# cslr_srio_001 register map
Vendor: Texas Instruments
Peripheral module from a debugger description file.
Registers are 32-bit, read-write, reset 0x0 unless marked. A register's access mark holds for its fields unless they carry their own. Offsets are as the file gives them; lines under a group give offsets from that group; [hi:lo] are bit positions; {n}, {i} and the like mark numbered series; 'fields as' and 'values as' point back to an identical list; <NAME> marks a mode.

## SRIO — 1x/4x Sreial RapidIO
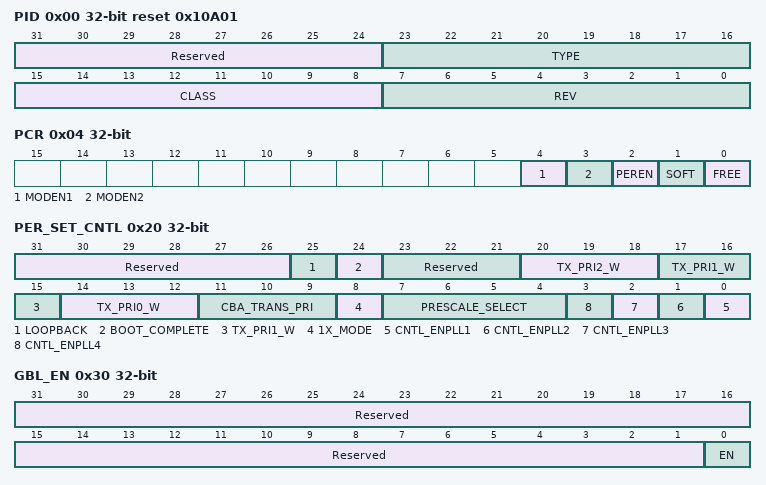
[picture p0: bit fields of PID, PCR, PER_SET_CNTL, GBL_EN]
0x00 PID access not given reset 0x10A01 (reset mask 0xFFFFFF) — Periperal Identification Register
  [31:24] Reserved — (access N)
  [23:16] TYPE ro — Type identifies the type of the peripheral RIO
  [15:8] CLASS ro — Class identifies the class switch fabric
  [7:0] REV ro — Revisions level of the specific instance of the peripheral
0x04 PCR — Peripheral Control Register
  [4] MODEN1 — Data Transmit Register(Read/Write)
  [3] MODEN2 — Data Transmit Register(Read/Write)
  [2] PEREN — Data Transmit Register(Read/Write)
  [1] SOFT — Data Transmit Register(Read/Write)
  [0] FREE — Data Transmit Register(Read/Write)
0x20 PER_SET_CNTL access not given (reset mask 0x31FFFFF)
  [31:26] Reserved — (access N)
  [25] LOOPBACK rw — Data Transmit Register(Read/Write)
  [24] BOOT_COMPLETE rw — Data Transmit Register(Read/Write)
  [23:21] Reserved — (access N)
  [20:18] TX_PRI2_W rw — Data Transmit Register(Read/Write)
  [17:15] TX_PRI1_W rw — Data Transmit Register(Read/Write)
  [14:12] TX_PRI0_W rw — Data Transmit Register(Read/Write)
  [11:9] CBA_TRANS_PRI rw — Data Transmit Register(Read/Write)
  [8] 1X_MODE rw — Data Transmit Register(Read/Write)
  [7:4] PRESCALE_SELECT rw — Data Transmit Register(Read/Write)
  [n-1] CNTL_ENPLL{n} rw (n=1..4) — Data Transmit Register(Read/Write)
0x30 GBL_EN access not given (reset mask 0x1) — Peripheral Global Enable
  [31:1] Reserved — (access N)
  [0] EN rw — Controls reset to all clock domains within the peripheral
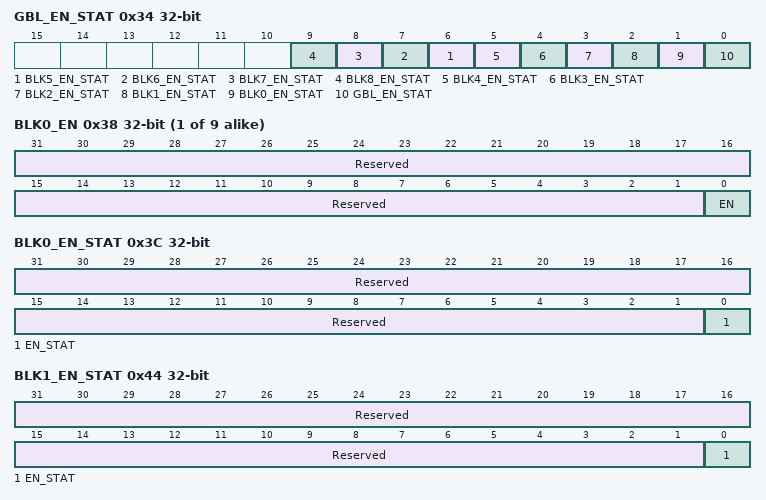
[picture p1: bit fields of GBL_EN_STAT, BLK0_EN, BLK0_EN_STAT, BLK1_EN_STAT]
0x34 GBL_EN_STAT ro
  [n+1] BLK{n}_EN_STAT (n=5..8) — Sample rate generator clock divider. This value is used as the divide-down number to generate the required sample rate generator clock frequency. Default value is 1.
  [5] BLK4_EN_STAT — Frame Width. Determines the width of the frame sync pulse, FSG, during its active period. Range: up to 28 ; 1 to 256 CLKG periods.
  [4] BLK3_EN_STAT — Frame Period. This determines when the next frame sync signal should become active. Range: up to 212 ; 1 to 4096 CLKG periods.
  [3] BLK2_EN_STAT — Sample Rate Generator Transmit frame synchronization mode. Used when FSXM=1 in PCR.
  [2] BLK1_EN_STAT — McBSP Sample Rate Generator Clock Mode
  [1] BLK0_EN_STAT — CLKS Polarity Clock Edge Select. Only used when the external clock CLKS drives the sample rate generator clock (CLKSM=0).
  [0] GBL_EN_STAT — Peripheral Global Enable Status
{0x38+8i} BLK{i}_EN access not given (reset mask 0x1) (i=0..8)
  [31:1] Reserved — (access N)
  [0] EN rw
0x3C BLK0_EN_STAT access not given (reset mask 0x1)
  [31:1] Reserved — (access N)
  [0] EN_STAT ro
    0=CHDISABLE
0x44 BLK1_EN_STAT access not given (reset mask 0x1)
  [31:1] Reserved — (access N)
  [0] EN_STAT ro
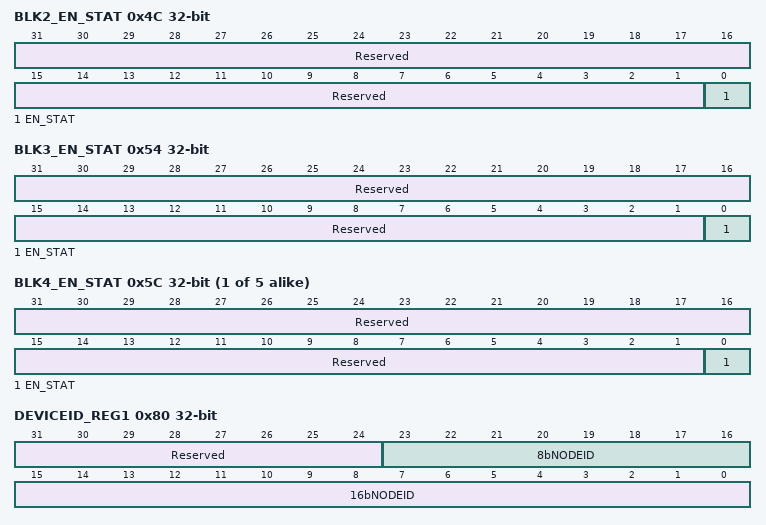
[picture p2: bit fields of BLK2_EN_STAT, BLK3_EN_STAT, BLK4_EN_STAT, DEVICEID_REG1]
0x4C BLK2_EN_STAT access not given (reset mask 0x1)
  [31:1] Reserved — (access N)
  [0] EN_STAT ro
0x54 BLK3_EN_STAT access not given (reset mask 0x1)
  [31:1] Reserved — (access N)
  [0] EN_STAT ro
    0=CHDISABLE
{0x3C+8i} BLK{i}_EN_STAT access not given (reset mask 0x1) (i=4..8)
  [31:1] Reserved — (access N)
  [0] EN_STAT ro
0x80 DEVICEID_REG1 access not given (reset mask 0xFFFFFF)
  [31:24] Reserved — (access N)
  [23:16] 8bNODEID rw
  [15:0] 16bNODEID rw
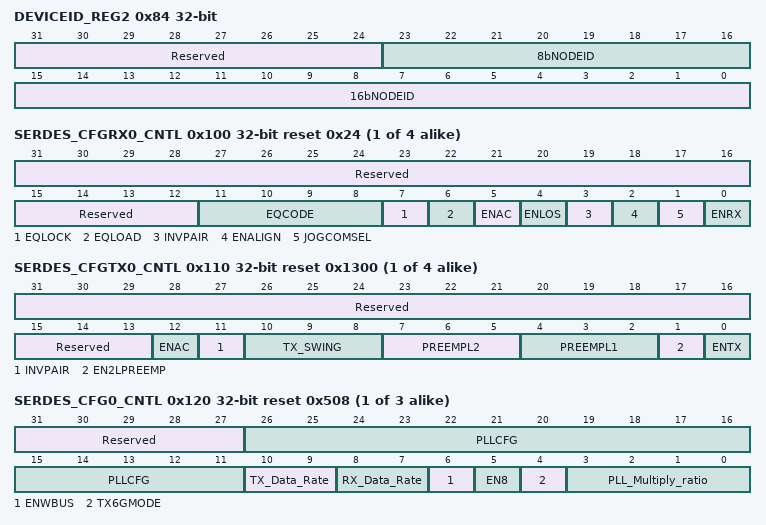
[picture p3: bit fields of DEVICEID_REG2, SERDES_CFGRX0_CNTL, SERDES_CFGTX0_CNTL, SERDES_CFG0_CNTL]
0x84 DEVICEID_REG2 access not given (reset mask 0xFFFFFF)
  fields as DEVICEID_REG1
{0x100+4i} SERDES_CFGRX{i}_CNTL access not given reset 0x24 (reset mask 0xFFF) (i=0..3) — SerDes CFGRX{i} Bus Register
  [31:12] Reserved — (access N)
  [11:8] EQCODE rw
  [7] EQLOCK rw
  [6] EQLOAD rw
  [5] ENAC rw
  [4] ENLOS rw
  [3] INVPAIR rw
  [2] ENALIGN rw
  [1] JOGCOMSEL rw
  [0] ENRX rw
{0x110+4i} SERDES_CFGTX{i}_CNTL access not given reset 0x1300 (reset mask 0x1FFF) (i=0..3) — SerDes TX Channel {i} CFG Regr
  [31:13] Reserved — (access N)
  [12] ENAC rw
  [11] INVPAIR rw
  [10:8] TX_SWING rw
  [7:5] PREEMPL2 rw
  [4:2] PREEMPL1 rw
  [1] EN2LPREEMP rw
  [0] ENTX rw
{0x120+4i} SERDES_CFG{i}_CNTL access not given reset 0x508 (reset mask 0x7FFFFFF) (i=0..2) — SerDes Macro {i}CFG Control Reg
  [31:27] Reserved — (access N)
  [26:11] PLLCFG rw
  [10:9] TX_Data_Rate rw
  [8:7] RX_Data_Rate rw
  [6] ENWBUS rw
  [5] EN8 rw
  [4] TX6GMODE rw
  [3:0] PLL_Multiply_ratio rw
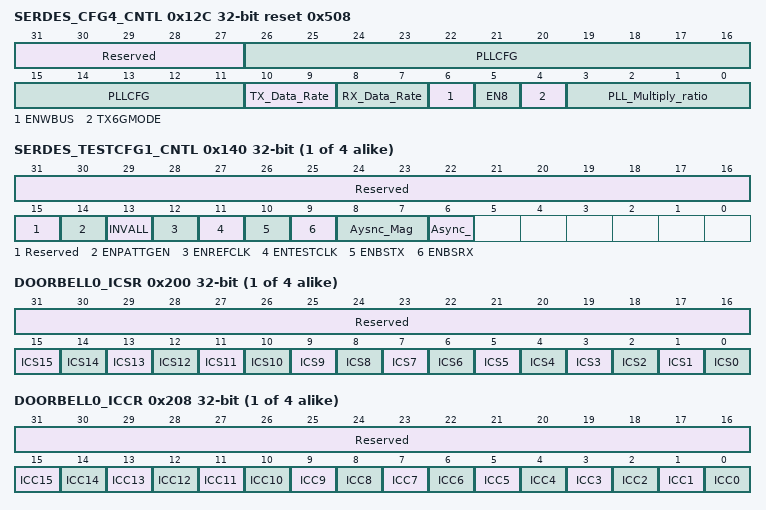
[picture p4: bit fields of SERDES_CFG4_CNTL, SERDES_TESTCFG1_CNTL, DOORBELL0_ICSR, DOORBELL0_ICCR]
0x12C SERDES_CFG4_CNTL access not given reset 0x508 (reset mask 0x7FFFFFF) — SerDes Macro 3CFG Control Reg
  fields as SERDES_CFG0_CNTL
{0x13C+4i} SERDES_TESTCFG{i}_CNTL access not given (reset mask 0x7FFF) (i=1..4) — SerDes TESTCFG BUS Register
  [31:15] Reserved — (access N)
  [14] ENPATTGEN rw
  [13] INVALL rw
  [12] ENREFCLK rw
  [11] ENTESTCLK rw
  [10] ENBSTX rw
  [9] ENBSRX rw
  [8:7] Aysnc_Mag rw
  [6] Async_
Polarity rw
  [5] Async_Ramp rw
  [4:2] TESTPATT rw
  [1] PADL rw
  [0] LOOPBACK rw
{0x200+0x10*i} DOORBELL{i}_ICSR access not given (reset mask 0xFFFF) (i=0..3) — Interrupt Condition Status Register (ICSR)
  [31:16] Reserved — (access N)
  [n] ICS{n} rw (n=0..15)
{0x208+0x10*i} DOORBELL{i}_ICCR access not given (reset mask 0xFFFF) (i=0..3) — Interrupt Condition Clear Register (ICCR)
  [31:16] Reserved — (access N)
  [n] ICC{n} rw (n=0..15)
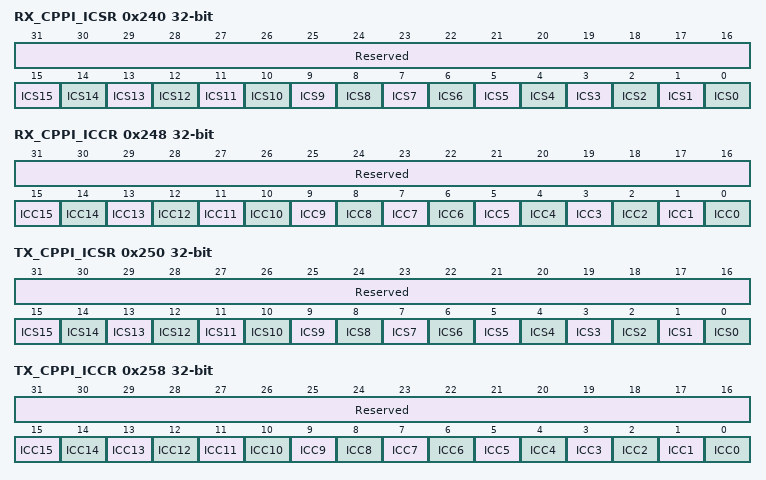
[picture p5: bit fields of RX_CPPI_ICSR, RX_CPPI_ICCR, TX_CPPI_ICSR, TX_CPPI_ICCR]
0x240 RX_CPPI_ICSR access not given (reset mask 0xFFFF) — RIO_RX_CPPI Interrupt Condition Status Register (ICSR)
  [31:16] Reserved — (access N)
  [n] ICS{n} rw (n=0..15)
0x248 RX_CPPI_ICCR access not given (reset mask 0xFFFF) — RIO_RX_CPPI Interrupt Condition Clear Register (ICCR)
  [31:16] Reserved — (access N)
  [n] ICC{n} rw (n=0..15)
0x250 TX_CPPI_ICSR access not given (reset mask 0xFFFF) — RIO_TX_CPPI Interrupt Condition Status Register (ICSR)
  [31:16] Reserved — (access N)
  [n] ICS{n} rw (n=0..15)
0x258 TX_CPPI_ICCR access not given (reset mask 0xFFFF) — RIO_TX_CPPI Interrupt Condition Clear Register (ICCR)
  [31:16] Reserved — (access N)
  [n] ICC{n} rw (n=0..15)
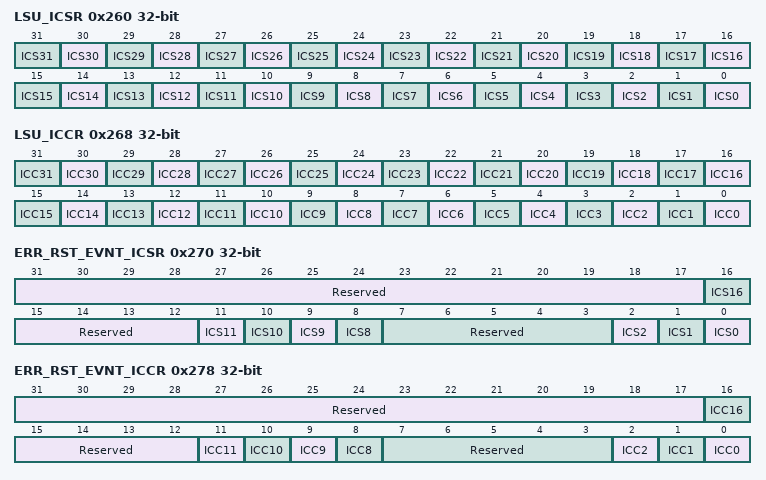
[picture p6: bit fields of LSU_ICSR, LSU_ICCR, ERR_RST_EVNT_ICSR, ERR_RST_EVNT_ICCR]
0x260 LSU_ICSR — LSU Load/Store Module Interrupts Condition Status Register (ICSR)
  [n] ICS{n} (n=0..31)
0x268 LSU_ICCR — LSU Load/Store Module Interrupts Condition Clear Register (ICCR)
  [n] ICC{n} (n=0..31)
0x270 ERR_RST_EVNT_ICSR access not given (reset mask 0x10F07) — ERR_RST_EVNT Error, Reset, and Special Event Interrupt Condition Status Register (ICSR)
  [31:17] Reserved — (access N)
  [16] ICS16 rw
  [15:12] Reserved — (access N)
  [n] ICS{n} rw (n=8..11)
  [7:3] Reserved — (access N)
  [2] ICS2 rw
  [1] ICS1 rw
  [0] ICS0 rw
0x278 ERR_RST_EVNT_ICCR access not given (reset mask 0x10F07) — ERR_RST_EVNT Error, Reset, and Special Event Interrupt Condition Clear Register (ICCR)
  [31:17] Reserved — (access N)
  [16] ICC16 rw
  [15:12] Reserved — (access N)
  [n] ICC{n} rw (n=8..11)
  [7:3] Reserved — (access N)
  [2] ICC2 rw
  [1] ICC1 rw
  [0] ICC0 rw
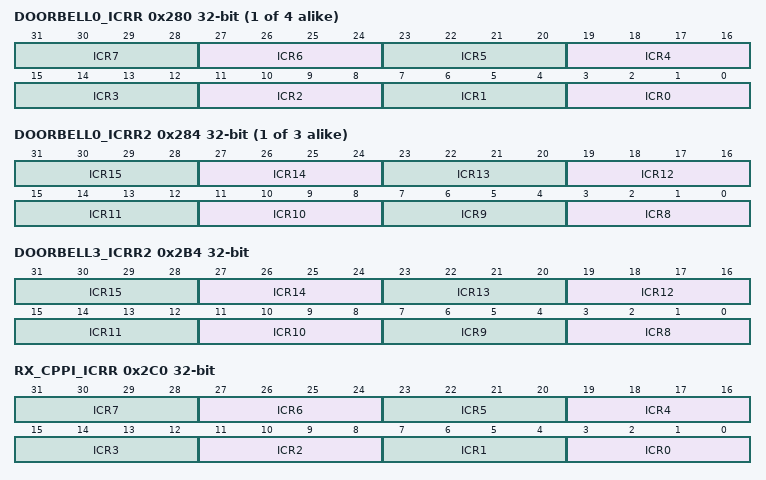
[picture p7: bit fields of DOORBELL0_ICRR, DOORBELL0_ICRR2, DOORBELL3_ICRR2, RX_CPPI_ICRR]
{0x280+0x10*i} DOORBELL{i}_ICRR (i=0..3) — DOORBELL{i}_ICRR CPU Servicing Interrupt Condition Routing Register (ICRR)
  [4n+3:4n] ICR{n} (n=0..7)
{0x284+0x10*i} DOORBELL{i}_ICRR2 (i=0..2) — DOORBELL{i}_ICRR2 CPU Servicing Interrupt Condition Routing Register (ICRR)
  [4n-29:4n-32] ICR{n} (n=8..15)
0x2B4 DOORBELL3_ICRR2 — DOORBELL3_ICRR2 CPU Servicing Interrupt Condition Routing Register (ICCR)
  [4n-29:4n-32] ICR{n} (n=8..15)
0x2C0 RX_CPPI_ICRR — RX CPPI CPU Servicing Interrupt Condition Routing Register (ICRR)
  [4n+3:4n] ICR{n} (n=0..7)
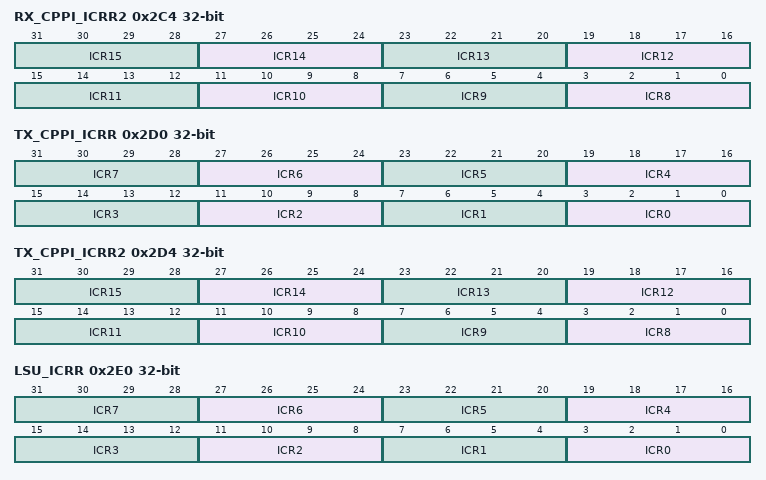
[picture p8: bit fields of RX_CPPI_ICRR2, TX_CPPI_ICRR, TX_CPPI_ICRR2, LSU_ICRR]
0x2C4 RX_CPPI_ICRR2 — RX CPPI CPU Servicing Interrupt Condition Routing Register (ICCR)
  [4n-29:4n-32] ICR{n} (n=8..15)
0x2D0 TX_CPPI_ICRR — TX CPPI CPU Servicing Interrupt Condition Routing Register (ICRR)
  [4n+3:4n] ICR{n} (n=0..7)
0x2D4 TX_CPPI_ICRR2 — TX CPPI CPU Servicing Interrupt Condition Routing Register (ICRR)
  [4n-29:4n-32] ICR{n} (n=8..15)
0x2E0 LSU_ICRR — Load/Store Module Interrupt Condition Routing Register (ICRR)
  [4n+3:4n] ICR{n} (n=0..7)
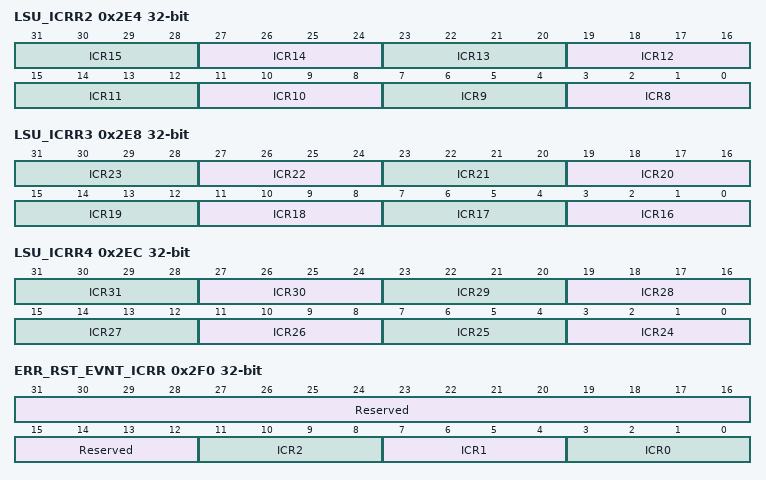
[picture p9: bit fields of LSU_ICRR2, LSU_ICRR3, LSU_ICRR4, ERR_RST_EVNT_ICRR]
0x2E4 LSU_ICRR2 — Load/Store Module Interrupt Condition Routing Register (ICRR)
  [4n-29:4n-32] ICR{n} (n=8..15)
0x2E8 LSU_ICRR3 — Load/Store Module Interrupt Condition Routing Register (ICRR)
  [4n-61:4n-64] ICR{n} (n=16..23)
0x2EC LSU_ICRR4 — Load/Store Module Interrupt Condition Routing Register (ICRR)
  [4n-93:4n-96] ICR{n} (n=24..31)
0x2F0 ERR_RST_EVNT_ICRR access not given (reset mask 0xFFF) — Error, Reset, and Special Event Interrupt Condition Routing Register (ICRR)
  [31:12] Reserved — (access N)
  [11:8] ICR2 rw
  [7:4] ICR1 rw
  [3:0] ICR0 rw
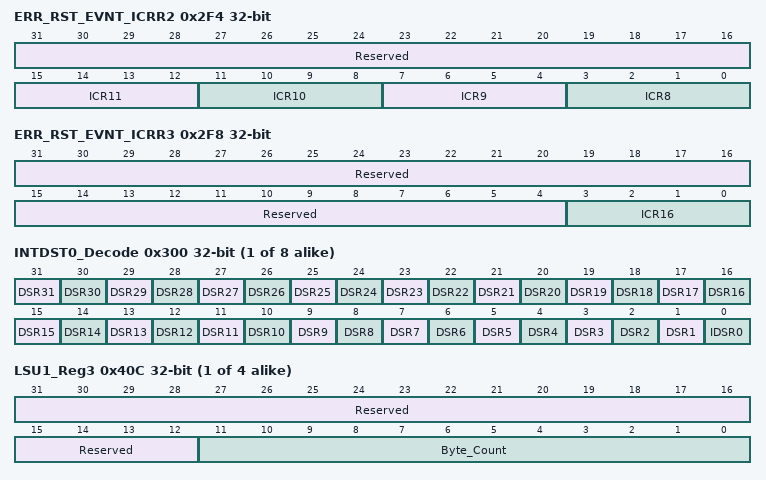
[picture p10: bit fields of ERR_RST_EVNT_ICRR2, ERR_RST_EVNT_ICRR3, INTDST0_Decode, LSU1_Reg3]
0x2F4 ERR_RST_EVNT_ICRR2 access not given (reset mask 0xFFFF) — Error, Reset, and Special Event Interrupt Condition Routing Register (ICRR)
  [31:16] Reserved — (access N)
  [4n-29:4n-32] ICR{n} rw (n=8..11)
0x2F8 ERR_RST_EVNT_ICRR3 access not given (reset mask 0xF) — Error, Reset, and Special Event Interrupt Condition Routing Register (ICRR)
  [31:4] Reserved — (access N)
  [3:0] ICR16 rw
{0x300+4i} INTDST{i}_Decode (i=0..7) — RIO_INTDSTn_Decode Interrupt Status Decode Register
  [n] DSR{n} (n=1..31), [0] IDSR0
{0x320+4i} INTDST{i}_Rate_CNTL (i=0..7) — RIO_INTDSTn_Rate_CNTL Interrupt Rate Control Counter Register
  [31:0] Count_Down_value
{0x3E0+0x20*i} LSU{i}_Reg0 (i=1..4) — Load/Store Registers for RapidIO
  [31:0] RapidIO_Address_MSB
{0x3E4+0x20*i} LSU{i}_Reg1 (i=1..4) — Load/Store Registers for RapidIO
  [31:0] Address_LSB_Config_offset
{0x3E8+0x20*i} LSU{i}_Reg2 (i=1..4) — Load/Store Registers for RapidIO
  [31:0] DSP_Address
{0x3EC+0x20*i} LSU{i}_Reg3 access not given (reset mask 0xFFF) (i=1..4) — Load/Store Registers for RapidIO
  [31:12] Reserved — (access N)
  [11:0] Byte_Count rw
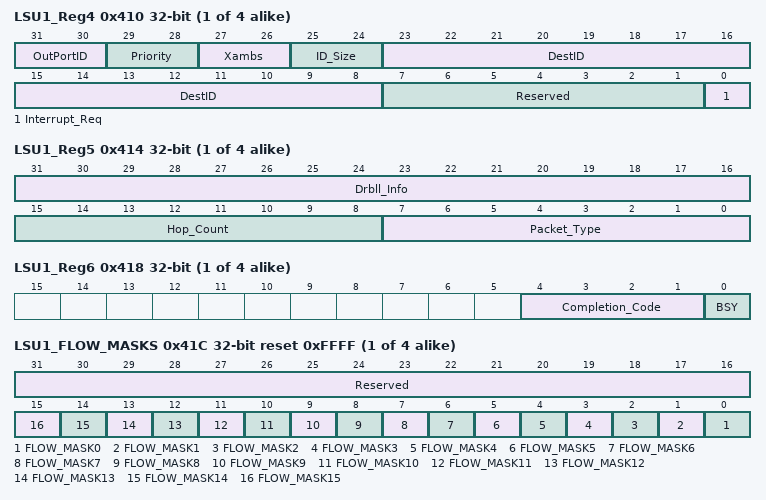
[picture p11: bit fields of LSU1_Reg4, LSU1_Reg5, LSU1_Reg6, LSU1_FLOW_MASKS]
{0x3F0+0x20*i} LSU{i}_Reg4 access not given (reset mask 0xFFFFFF01) (i=1..4) — Load/Store Registers for RapidIO
  [31:30] OutPortID rw
  [29:28] Priority rw
  [27:26] Xambs rw
  [25:24] ID_Size rw
  [23:8] DestID rw
  [7:1] Reserved — (access N)
  [0] Interrupt_Req rw
{0x3F4+0x20*i} LSU{i}_Reg5 (i=1..4) — Load/Store Registers for RapidIO
  [31:16] Drbll_Info, [15:8] Hop_Count, [7:0] Packet_Type
{0x3F8+0x20*i} LSU{i}_Reg6 (i=1..4) — Load/Store Registers for RapidIO
  [4:1] Completion_Code, [0] BSY
{0x3FC+0x20*i} LSU{i}_FLOW_MASKS access not given reset 0xFFFF (reset mask 0xFFFF) (i=1..4) — Core0 LSUCongestion Control Flow Masks
  [31:16] Reserved — (access N)
  [n] FLOW_MASK{n} rw (n=0..15)
{0x500+4i} Queue{i}_TxDMA_HDP (i=0..15) — TX DMA State HDP
  [31:0] TX_HDP
{0x580+4i} Queue{i}_TxDMA_CP (i=0..15) — TX DMA State CP
  [31:0] TX_CP
{0x600+4i} Queue{i}_RXDMA_HDP (i=0..15) — RX DMA State HDP
  [31:0] RX_HDP
{0x680+4i} Queue{i}_RXDMA_CP (i=0..15) — RX DMA State CP
  [31:0] RX_CP
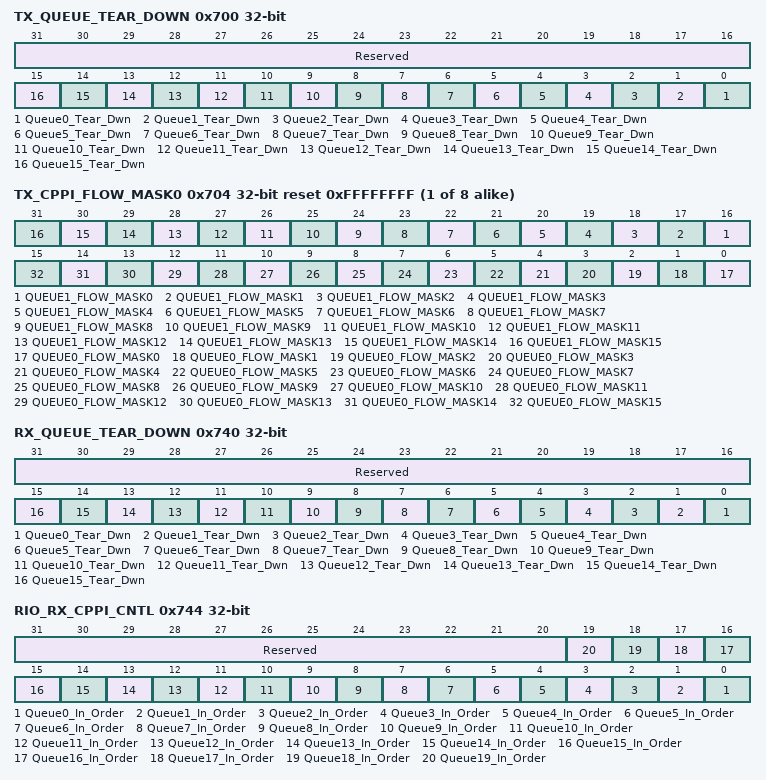
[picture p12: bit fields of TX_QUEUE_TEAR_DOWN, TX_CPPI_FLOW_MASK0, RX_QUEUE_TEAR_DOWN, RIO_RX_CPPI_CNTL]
0x700 TX_QUEUE_TEAR_DOWN access not given (reset mask 0xFFFF)
  [31:16] Reserved — (access N)
  [n] Queue{n}_Tear_Dwn wo (n=0..15)
{0x704+4i} TX_CPPI_FLOW_MASK{i} reset 0xFFFFFFFF (i=0..7) — TX CPPI SUPPORTED FLOW MASK
  [n+16] QUEUE{2i+1}_FLOW_MASK{n} (n=0..15), [n] QUEUE{2i}_FLOW_MASK{n} (n=0..15)
0x740 RX_QUEUE_TEAR_DOWN access not given (reset mask 0xFFFF)
  [31:16] Reserved — (access N)
  [n] Queue{n}_Tear_Dwn wo (n=0..15)
0x744 RIO_RX_CPPI_CNTL access not given (reset mask 0xFFFFF) — RX CPPI Mode Register
  [31:20] Reserved — (access N)
  [n] Queue{n}_In_Order wo (n=0..19)
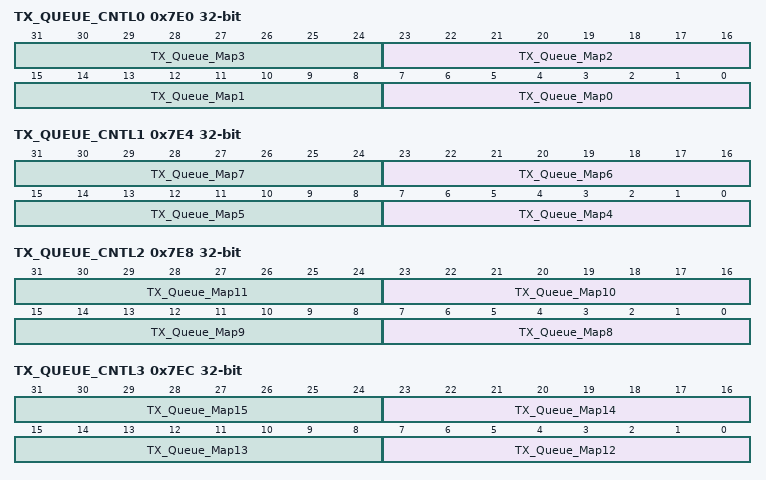
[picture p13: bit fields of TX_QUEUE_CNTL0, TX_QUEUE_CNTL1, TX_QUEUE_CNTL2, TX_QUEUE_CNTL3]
0x7E0 TX_QUEUE_CNTL0 — TX CPPI Weighted Round Robin Control Register 0
  [8n+7:8n] TX_Queue_Map{n} (n=0..3)
0x7E4 TX_QUEUE_CNTL1 — TX CPPI Weighted Round Robin Control Register 1
  [8n-25:8n-32] TX_Queue_Map{n} (n=4..7)
0x7E8 TX_QUEUE_CNTL2 — TX CPPI Weighted Round Robin Control Register 2
  [8n-57:8n-64] TX_Queue_Map{n} (n=8..11)
0x7EC TX_QUEUE_CNTL3 — TX CPPI Weighted Round Robin Control Register 3
  [8n-89:8n-96] TX_Queue_Map{n} (n=12..15)
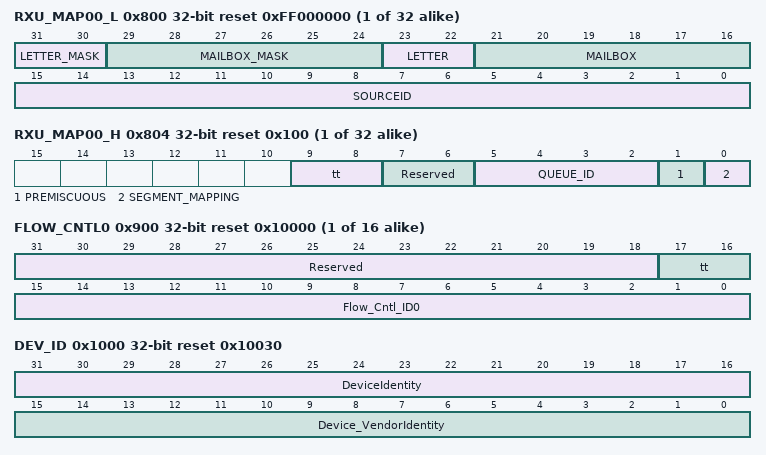
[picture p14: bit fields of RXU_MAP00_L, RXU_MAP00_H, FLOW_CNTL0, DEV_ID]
{0x800+8i} RXU_MAP{i:02}_L reset 0xFF000000 (i=0..31) — Mailbox-to-Queue Mapping Register
  [31:30] LETTER_MASK, [29:24] MAILBOX_MASK, [23:22] LETTER, [21:16] MAILBOX, [15:0] SOURCEID
{0x804+8i} RXU_MAP{i:02}_H access not given reset 0x100 (reset mask 0x33F) (i=0..31) — Mailbox-to-Queue Mapping Register
  [9:8] tt rw
  [7:6] Reserved — (access N)
  [5:2] QUEUE_ID rw
  [1] PREMISCUOUS rw
  [0] SEGMENT_MAPPING rw
{0x900+4i} FLOW_CNTL{i} access not given reset 0x10000 (reset mask 0x3FFFF) (i=0..15) — Flow Control Table Entry Register
  [31:18] Reserved — (access N)
  [17:16] tt rw
  [15:0] Flow_Cntl_ID{i} rw
0x1000 DEV_ID ro reset 0x10030 — Device Identity CAR Register
  [31:16] DeviceIdentity, [15:0] Device_VendorIdentity
0x1004 DEV_INFO access not given reset 0x112 (reset mask 0xFFFF) — Device Information CAR Register
  [31:16] Reserved — (access N)
  [15:8] DeviceRev ro
  [7:4] MajorRev ro
  [3:0] MinorRev ro
0x1008 ASBLY_ID ro reset 0x300001 — Assembly Identity CAR Register
  [31:16] Assy_Identity, [15:0] Assy_VendorIdentity
0x100C ASBLY_INFO ro reset 0x10100 — Assembly Information CAR Register
  [31:16] AssyRev, [15:0] ExtendedFeaturesPtr
0x1010 PE_FEAT ro reset 0x60000099 — Processing Element Features CAR Register
  [31] Bridge, [30] Memory, [29] Processor, [28] Switch, [7] Flow_Control_Support, [6] Retransmit_Suppression_Support, [5] CRF_Support, [4] Common_Transport_Large_System_Support, [4] Common_Transport_Large_System_Support, [3] Extended_features, [2:0] Extended_addressing_support
0x1014 SW_PORT access not given reset 0x100 (reset mask 0xFFFF) — Switch Port Information CAR Register
  [31:16] Reserved — (access N)
  [15:8] PortTotal ro
  [7:0] PortNumber ro
0x1018 SRC_OP access not given reset 0xFDF4 (reset mask 0x3FDF7) — Source Operations CAR Register
  [31:18] Reserved — (access N)
  [17:16] Implementation_Defined ro
  [15] Read ro
  [14] Write ro
  [13] Streaming_write ro
  [12] Write_with_response ro
  [11] Data_Message ro
  [10] DoorBell ro
  [9] Reserved — (access N)
  [8] Atomic_test_and_swap ro
  [7] Atomic_increment ro
  [6] Atomic_decrement ro
  [5] Atomic_set ro
  [4] Atomic_clear ro
  [3] Reserved — (access N)
  [2] Portwrite ro
  [1:0] Implementation_Defined ro
0x101C DEST_OP access not given reset 0xFDF4 (reset mask 0x3FDF7) — Destination Operations CAR Register
  [31:18] Reserved — (access N)
  [17:16] Implementation_Defined ro
  [15] Read ro
  [14] Write ro
  [13] Streaming-write ro
  [12] Write-with-response ro
  [11] Data_Message ro
  [10] DoorBell ro
  [9] Reserved — (access N)
  [8] Atomic_test-and-swap ro
  [7] Atomic_increment ro
  [6] Atomic_decrement ro
  [5] Atomic_set ro
  [4] Atomic_clear ro
  [3] Reserved — (access N)
  [2] Portwrite ro
  [1:0] Implementation_Defined ro
0x104C PE_LL_CTL access not given reset 0x1 (reset mask 0x7) — Processing Element Logical Layer Control CSR Register
  [31:3] Reserved — (access N)
  [2:0] Extended_Addressing_Control rw
0x1058 LCL_CFG_HBAR access not given (reset mask 0x7FFFFFFF) — Local Configuration Space Base Address 0 CSR Register
  [31] Reserved — (access N)
  [30:15] LCSBA ro
  [14:0] LCSBA ro
0x105C LCL_CFG_BAR ro — Local Configuration Space Base Address 1 CSR Register
  [31] LCSBA, [30:0] LCSBA
0x1060 BASE_ID access not given reset 0xFFFFFF (reset mask 0xFFFFFF) — Base Device ID CSR Register
  [31:24] Reserved — (access N)
  [23:16] Base_deviceID rw
  [15:0] Large_Base_deviceID rw
0x1068 HOST_BASE_ID_LOCK access not given (reset mask 0xFFFF) — Host Base Device ID Lock CSR Register
  [31:16] Reserved — (access N)
  [15:0] Host_Base_DeviceID rw
0x106C COMP_TAG — Component Tag CSR Register
  [31:0] Component_tag
0x1100 SP_MB_HEAD ro reset 0x10000001 — 1x/4x LP-Serial Port Maintenance Block Header Register
  [31:16] EF_PTR, [15:0] EF_ID
0x1120 SP_LT_CTL reset 0xFFFFFFFF — Port Link Time-Out Control CSR Register
  [31:0] Time_Out_Value
0x1124 SP_RT_CTL reset 0xFFFFFFFF — Port Response Time-Out Control CSR Register
  [31:0] Time_Out_Value
0x113C SP_GEN_CTL access not given (reset mask 0xE0000000) — Port General Control CSR Register
  [31] Host rw
  [30] Master_Enable rw
  [29] Discovered rw
  [28:0] Reserved — (access N)
{0x1140+0x20*i} SP{i}_LM_REQ access not given (reset mask 0x7) (i=0..3) — Port {i} Link Maintenance Request CSR Register
  [31:3] Reserved — (access N)
  [2:0] Command rw
{0x1144+0x20*i} SP{i}_LM_RESP access per field (i=0..3) — Port {i} Link Maintenance Response CSR Register
  [31] response_valid ro, [9:5] ackID_status rw, [4:0] link_status rw
{0x1148+0x20*i} SP{i}_ACKID_STAT access not given (reset mask 0x1F001F1F) (i=0..3) — Port {i} Local AckID Status CSR Register
  [31:29] Reserved — (access N)
  [28:24] Inbound_ackID rw
  [23:13] Reserved — (access N)
  [12:8] Outstanding_ackID rw
  [7:5] Reserved — (access N)
  [4:0] Outbound_ackID rw
{0x1158+0x20*i} P{i}_ERR_STAT access not given reset 0x1 (reset mask 0x71F0717) (i=0..3) — Port {i} Error and Status CSR Register
  [31:27] Reserved — (access N)
  [26] Output_Packet_dropped ro
  [25] Output_Failed_encountered ro
  [24] Output_Degraded_encountered ro
  [23:21] Reserved — (access N)
  [20] Output_Retry_encountered ro
  [19] Output_Retried ro
  [18] Output_Retry_stopped ro
  [17] Output_Error_encountered ro
  [16] Output_Error_stopped ro
  [15:11] Reserved — (access N)
  [10] Input_Retry_stopped ro
  [9] Input_Error_encountered ro
  [8] Input_Error_stopped ro
  [7:5] Reserved — (access N)
  [4] Port_write_Pending ro
  [3] Reserved — (access N)
  [2] Port_Error ro
  [1] Port_OK ro
  [0] Port_Uninitialized ro
{0x115C+0x20*i} SP{i}_CTL access per field reset 0x80001 (i=0..3) — Port {i} Control CSR Register
  [31:30] Port_Width ro, [29:27] Initialized_Port_Width ro, [26:24] Port_Width_Override rw, [23] Port_Disable rw, [22] Output_Port_Enable rw, [21] Input_Port_Enable rw, [20] Error_Checking_Disable rw, [19] Multicast_event_Participant ro, [3] Stop_Port_Failed_encountered_Enable rw, [2] Drop_Packet_Enable rw, [1] Port_Lockout rw, [0] Port_Type ro
0x2000 ERR_RPT_BH ro reset 0x7 — Error Reporting Block Header Register
  [31:16] EF_PTR, [15:0] EF_ID
0x2008 ERR_DET — Logical/Transport Layer Error Detect CSR Register
  [31] IO_error_response, [30] Message_error_response, [29] GSM_error_response, [28] Message_Format_Error, [27] Illegal_transaction_decode, [26] Illegal_transaction_target_error, [25] Message_Request_Timeout, [24] Packet_Response_Timeout, [23] Unsolicited_Response, [22] Unsupported_Transaction, [7] RX_CPPI_Security_Violation, [6] RX_IO_DMA_Access_Error, [5:0] Implementation_Specific_error
0x200C ERR_EN — Logical/Transport Layer Error Enable CSR Register
  [31] IO_error_response_enable, [30] Message_error_response_enable, [29] GSM_error_response_enable, [28] Message_Format_Error_enable, [27] Illegal_transaction_decode_enable, [26] Illegal_transaction_target_error_enable, [25] Message_Request_Timeout_enable, [24] Packet_Response_Timeout_enable, [23] Unsolicited_Response_enable, [22] Unsupported_Transaction_enable, [7] RX_CPPI_Security_Violation_enable, [6] RX_IO_DMA_Access_Error_enable, [5:0] Implementation_Specific_error_enable
0x2010 H_ADDR_CAPT ro — Logical/Transport Layer High Address Capture CSR Register
  [31:0] Address_63_32
0x2014 ADDR_CAPT access not given (reset mask 0xFFFFFFFB) — Logical/Transport Layer Address Capture CSR Register
  [31:3] Address_31_3 ro
  [2] Reserved — (access N)
  [1:0] Xamsbs ro
0x2018 ID_CAPT ro — Logical/Transport Layer Device ID Capture CSR Register
  [31:24] MSB_destinationID, [23:16] destinationID, [15:8] MSB_sourceID, [7:0] sourceID
0x201C CTRL_CAPT ro — Logical/Transport Layer Control Capture CSR Register
  [31:28] ftype, [27:24] ttype, [23:16] msg_info, [15:0] Implementation_specific
0x2028 PW_TGT_ID access not given (reset mask 0xFFFF0000) — Port-Write Target Device ID CSR Register
  [31:24] deviceID_msb ro
  [23:16] deviceID ro
  [15:0] Reserved — (access N)
0x202C PKT_TIME_LIVE access not given (reset mask 0xFFFF0000) — Packet Time-to-Live CSR Register
  [31:16] TimetoLive ro
  [15:0] Reserved — (access N)
{0x2040+0x40*i} SP{i}_ERR_DET access not given (reset mask 0x80FE003F) (i=0..3) — Port {i} Error Detect CSR Register
  [31] Implementation_specific_error ro
  [30:24] Reserved — (access N)
  [23] Received_Sbit_error ro
  [22] Received_corrupt_control_symbol ro
  [21] Receivedacknowledge_controlsymbol_unexpectedackID ro
  [20] Received_packetnotaccepted_control_symbol ro
  [19] Received_packet_with_unexpected_ackID ro
  [18] Received_packet_with_bad_CRC ro
  [17] Received_packet_exceeds_276Bytes ro
  [5] Non_outstanding_ackID ro
  [4] Protocol_error ro
  [3] Frame_toggle_edge_error ro
  [2] Delineation_error ro
  [1] Unsolicited_acknowledge_control_symbol ro
  [0] Link_timeout ro
{0x2044+0x40*i} SP{i}_RATE_EN access not given (reset mask 0x80FE003F) (i=0..3) — Port {i} Error Enable CSR Register
  [31] Implementation_specific_error_enable ro
  [30:24] Reserved — (access N)
  [23] Received_Sbit_error_enable ro
  [22] Received_corrupt_control_symbol_enable ro
  [21] Receivedacknowledge_controlsymbol_unexpectedackID_enable ro
  [20] Received_packetnotaccepted_control_symbol_enable ro
  [19] Received_packet_with_unexpected_ackID_enable ro
  [18] Received_packet_with_bad_CRC_enable ro
  [17] Received_packet_exceeds_276Bytes_enable ro
  [5] Non_outstanding_ackID_enable ro
  [4] Protocol_error_enable ro
  [3] Frame_toggle_edge_error_enable ro
  [2] Delineation_error_enable ro
  [1] Unsolicited_acknowledge_control_symbol_enable ro
  [0] Link_timeout_enable ro
{0x2048+0x40*i} SP{i}_ERR_ATTR_CAPT_DBG0 access not given (reset mask 0xDFFFFFF1) (i=0..2) — Port {i} Attributes Error Capture CSR Register
  [31:30] Info_type ro
  [29] Reserved — (access N)
  [28:24] Error_type ro
  [23:4] Implementation_Dependent ro
  [3:1] Reserved — (access N)
  [0] Capture_valid_info ro
{0x204C+0x40*i} SP{i}_ERR_CAPT_0_DBG1 ro (i=0..3) — Port {i} Packet/Control Symbol Error Capture CSR0 Register
  [31:0] Capture_0
{0x2050+0x40*i} SP{i}_ERR_CAPT_1_DBG2 ro (i=0..3) — Port {i} Packet Error Capture CSR1 Register
  [31:0] Capture_1
{0x2054+0x40*i} SP{i}_ERR_CAPT_2_DBG3 ro (i=0..3) — Port {i} Packet Error Capture CSR2 Register
  [31:0] Capture_2
{0x2058+0x40*i} SP{i}_ERR_CAPT_3_DBG4 ro (i=0..3) — Port {i} Packet Error Capture CSR3 Register
  [31:0] Capture_3
{0x2068+0x40*i} SP{i}_ERR_RATE access not given reset 0xFF000000 (reset mask 0xFF03FFFF) (i=0..3) — Port {i} Error Rate CSR Register
  [31:24] Error_Rate_Bias rw
  [23:18] Reserved — (access N)
  [17:16] Error_Rate_Recovery rw
  [15:8] Peak_Error_Rate rw
  [7:0] Error_Rate_Counter rw
{0x206C+0x40*i} SP{i}_ERR_THRESH access not given reset 0xFFFF0000 (reset mask 0xFFFF0000) (i=0..3) — Port {i} Error Rate Threshold CSR Register
  [31:24] Error_Rate_Failed_Threshold_Trigger rw
  [23:16] Error_Rate_Degraded_Threshold_Trigger rw
  [15:0] Reserved — (access N)
0x2108 SP3_ERR_ATTR_CAPT_DBG0 access not given (reset mask 0xDFFFFFF1) — Port 3+B6715 Attributes Error Capture CSR Register
  fields as SP0_ERR_ATTR_CAPT_DBG0
0x12000 SP_IP_DISCOVERY_TIMER access not given reset 0x90800000 (reset mask 0xF0F00000) — Port IP Discovery Timer in 4x mode Register
  [31:28] DISCOVERY_TIMER rw
  [27:24] Reserved — (access N)
  [23:20] PW_TIMER rw
  [19:0] Reserved — (access N)
0x12004 SP_IP_MODE access per field — Port IP Mode CSR Register
  [31:30] SP_MODE ro, [29] IDLE_ERR_DIS rw, [28] TX_FIFO_BYP ASS rw, [27] PW_DIS rw, [26] TGT_ID_DIS rw, [25] SELF_RST rw, [5] MLTC_EN rw, [4] MLTC_IRQ rw, [3] RST_EN rw, [2] RST_IRQ rw, [1] PW_EN rw, [0] PW_IRQ rw
0x12008 IP_PRESCAL — Serial Port IP Timer Prescalar Register
  [7:0] PRESCALE
{0x12010+4i} SP_IP_PW_IN_CAPT{i} (i=0..3) — Port-Write-In Capture {i} CSR Register
  [31:0] PW_CAPT{i}
{0x14000+0x100*i} SP{i}_RST_OPT (i=0..3) — Port {i} Reset Option CSR Register
  [7:0] PORT_ID
{0x14004+0x100*i} SP{i}_CTL_INDEP access not given reset 0x1000000 (reset mask 0x67F3FFC0) (i=0..3) — Port {i} Control Independent Reg Register
  [31] Reserved — (access N)
  [30] TX_FLW rw
  [29] SOFT_REC rw
  [28:27] Reserved — (access N)
  [26] FORCE_REINIT wo
  [25:24] TRANS_MODE rw
  [23] DEBUG rw
  [22] SEND_DBG_PKT rw
  [21] ILL_TRANS_EN rw
  [20] ILL_TRANS_ERR rw
  [19:18] Reserved — (access N)
  [17] MAX_RETRY_EN rw
  [16] MAX_RETRY_ERR rw
  [15:8] MAX_RETRY_THR rw
  [7] IRQ_EN rw
  [6] IRQ_ERR rw
  [5:0] Reserved — (access N)
{0x14008+0x100*i} SP{i}_SILENCE_TIMER access not given reset 0xB0000000 (reset mask 0xF0000000) (i=0..3) — Port {i} Silence Timer Register
  [31:28] SILENCE_TIMER rw
  [27:0] Reserved — (access N)
{0x1400C+0x100*i} SP{i}_MULT_EVNT_CS wo (i=0..3) — Port {i} Multicast-Event Control Symbol Request Register
  [31:0] MULT_EVNT_CS
{0x14014+0x100*i} RIO_SP{i}_CS_TX access not given (reset mask 0xFFFFF000) (i=0..3) — Port {i} Control Symbol Transmit Register
  [31:29] STYPE_0 rw
  [28:24] PAR_0 rw
  [23:19] PAR_1 rw
  [18:16] STYPE_1 rw
  [15:13] CMD rw
  [12] CS_EMB rw
  [11:0] Reserved — (access N)
